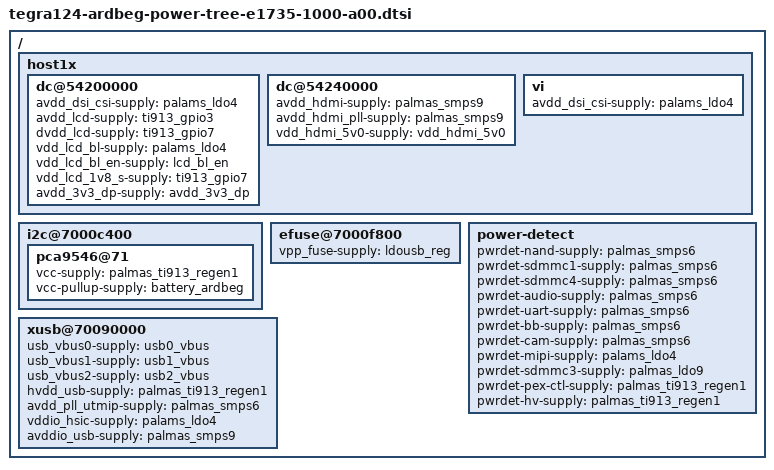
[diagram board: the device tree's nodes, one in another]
/*
 * arch/arm/boot/dts/tegra124-platforms/tegra124-ardbeg-power-tree-e1735-1000-a00.dtsi
 *
 * Copyright (c) 2014, NVIDIA CORPORATION.  All rights reserved.
 *
 * This program is free software; you can redistribute it and/or modify
 * it under the terms of the GNU General Public License as published by
 * the Free Software Foundation; either version 2 of the License, or
 * (at your option) any later version.
 *
 * This program is distributed in the hope that it will be useful, but WITHOUT
 * ANY WARRANTY; without even the implied warranty of MERCHANTABILITY or
 * FITNESS FOR A PARTICULAR PURPOSE.  See the GNU General Public License for
 * more details.
 *
 * You should have received a copy of the GNU General Public License along
 * with this program; if not, write to the Free Software Foundation, Inc.,
 * 51 Franklin Street, Fifth Floor, Boston, MA  02110-1301, USA.
 */

#include "tegra124-platforms/tegra124-ardbeg-pmic-e1735-1000-a00.dtsi"
#include "tegra124-platforms/tegra124-ardbeg-fixed-e1735-1000-a00.dtsi"

/ {
	host1x {
		/* tegradc.0 */
		dc@54200000 {
			avdd_dsi_csi-supply = <&palams_ldo4>;
			avdd_lcd-supply = <&ti913_gpio3>;
			dvdd_lcd-supply = <&ti913_gpio7>;
			vdd_lcd_bl-supply = <&palams_ldo4>;
			vdd_lcd_bl_en-supply = <&lcd_bl_en>;
			vdd_lcd_1v8_s-supply = <&ti913_gpio7>;
			avdd_3v3_dp-supply = <&avdd_3v3_dp>;
		};

		/* tegradc.1 */
		dc@54240000 {
			avdd_hdmi-supply = <&palmas_smps9>;
			avdd_hdmi_pll-supply = <&palmas_smps9>;
			vdd_hdmi_5v0-supply = <&vdd_hdmi_5v0>;
		};

		vi {
			avdd_dsi_csi-supply = <&palams_ldo4>;
		};
	};

	i2c@7000c400 {
		pca9546@71 {
			vcc-supply = <&palmas_ti913_regen1>;
			vcc-pullup-supply = <&battery_ardbeg>;
		};
	};

	efuse@7000f800 {
		vpp_fuse-supply = <&ldousb_reg>;
	};

	power-detect {
		pwrdet-nand-supply = <&palmas_smps6>;
		pwrdet-sdmmc1-supply = <&palmas_smps6>;
		pwrdet-sdmmc4-supply = <&palmas_smps6>;
		pwrdet-audio-supply = <&palmas_smps6>;
		pwrdet-uart-supply = <&palmas_smps6>;
		pwrdet-bb-supply = <&palmas_smps6>;
		pwrdet-cam-supply = <&palmas_smps6>;
		pwrdet-mipi-supply = <&palams_ldo4>;
		pwrdet-sdmmc3-supply = <&palmas_ldo9>;
		pwrdet-pex-ctl-supply = <&palmas_ti913_regen1>;
		pwrdet-hv-supply = <&palmas_ti913_regen1>;
	};

	xusb@70090000 {
		usb_vbus0-supply = <&usb0_vbus>;
		usb_vbus1-supply = <&usb1_vbus>;
		usb_vbus2-supply = <&usb2_vbus>;
		hvdd_usb-supply = <&palmas_ti913_regen1>;
		avdd_pll_utmip-supply = <&palmas_smps6>;
		vddio_hsic-supply = <&palams_ldo4>;
		avddio_usb-supply = <&palmas_smps9>;
	};
};
